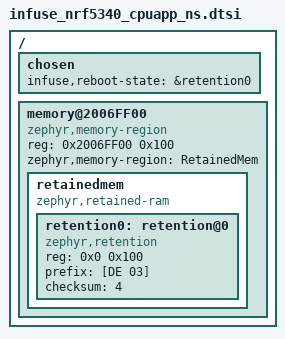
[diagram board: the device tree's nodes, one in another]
/ {
	chosen {
		infuse,reboot-state = &retention0;
	};

	/* End of application SRAM (not in shared SRAM) */
	memory@2006FF00 {
		compatible = "zephyr,memory-region", "mmio-sram";
		reg = <0x2006FF00 0x100>;
		zephyr,memory-region = "RetainedMem";
		status = "okay";

		retainedmem {
			compatible = "zephyr,retained-ram";
			status = "okay";
			#address-cells = <1>;
			#size-cells = <1>;

			retention0: retention@0 {
					compatible = "zephyr,retention";
					status = "okay";
					reg = <0x0 0x100>;
					prefix = [DE 03];
					checksum = <4>;
			};
		};
	};
};
